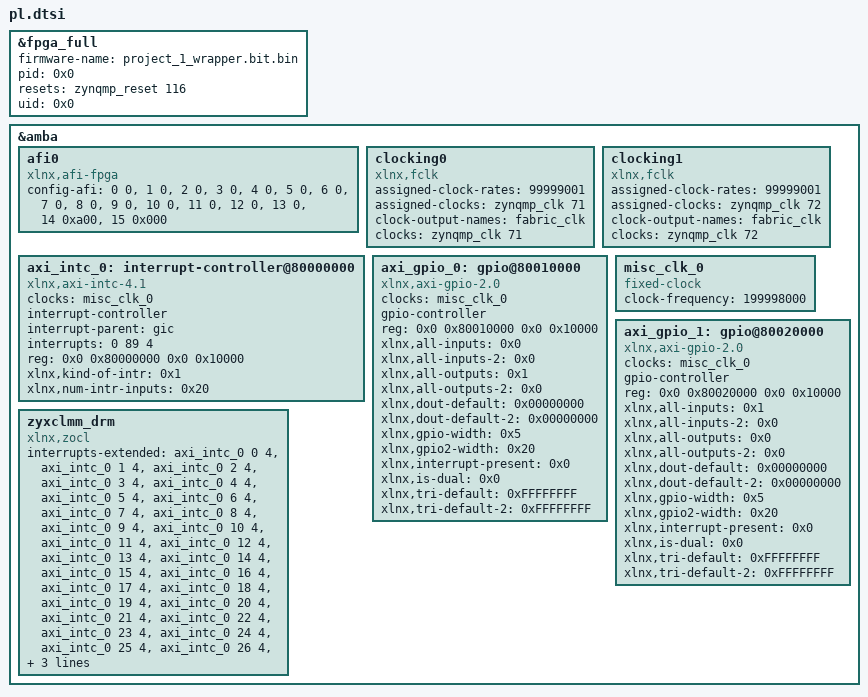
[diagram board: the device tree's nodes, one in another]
/*
 * CAUTION: This file is automatically generated by Xilinx.
 * Version: XSCT 2023.2
 * Today is: Thu Nov 14 10:54:46 2024
 */


/dts-v1/;
/plugin/;
&fpga_full {
	firmware-name = "project_1_wrapper.bit.bin";
	pid = <0x0>;
	resets = <&zynqmp_reset 116>;
	uid = <0x0>;
};
&amba {
	#address-cells = <2>;
	#size-cells = <2>;
	afi0: afi0 {
		compatible = "xlnx,afi-fpga";
		config-afi = < 0 0>, <1 0>, <2 0>, <3 0>, <4 0>, <5 0>, <6 0>, <7 0>, <8 0>, <9 0>, <10 0>, <11 0>, <12 0>, <13 0>, <14 0xa00>, <15 0x000>;
	};
	clocking0: clocking0 {
		#clock-cells = <0>;
		assigned-clock-rates = <99999001>;
		assigned-clocks = <&zynqmp_clk 71>;
		clock-output-names = "fabric_clk";
		clocks = <&zynqmp_clk 71>;
		compatible = "xlnx,fclk";
	};
	clocking1: clocking1 {
		#clock-cells = <0>;
		assigned-clock-rates = <99999001>;
		assigned-clocks = <&zynqmp_clk 72>;
		clock-output-names = "fabric_clk";
		clocks = <&zynqmp_clk 72>;
		compatible = "xlnx,fclk";
	};
	axi_intc_0: interrupt-controller@80000000 {
		#interrupt-cells = <2>;
		clock-names = "s_axi_aclk";
		clocks = <&misc_clk_0>;
		compatible = "xlnx,axi-intc-4.1", "xlnx,xps-intc-1.00.a";
		interrupt-controller ;
		interrupt-names = "irq";
		interrupt-parent = <&gic>;
		interrupts = <0 89 4>;
		reg = <0x0 0x80000000 0x0 0x10000>;
		xlnx,kind-of-intr = <0x1>;
		xlnx,num-intr-inputs = <0x20>;
	};
	axi_gpio_0: gpio@80010000 {
		#gpio-cells = <2>;
		clock-names = "s_axi_aclk";
		clocks = <&misc_clk_0>;
		compatible = "xlnx,axi-gpio-2.0", "xlnx,xps-gpio-1.00.a";
		gpio-controller ;
		reg = <0x0 0x80010000 0x0 0x10000>;
		xlnx,all-inputs = <0x0>;
		xlnx,all-inputs-2 = <0x0>;
		xlnx,all-outputs = <0x1>;
		xlnx,all-outputs-2 = <0x0>;
		xlnx,dout-default = <0x00000000>;
		xlnx,dout-default-2 = <0x00000000>;
		xlnx,gpio-width = <0x5>;
		xlnx,gpio2-width = <0x20>;
		xlnx,interrupt-present = <0x0>;
		xlnx,is-dual = <0x0>;
		xlnx,tri-default = <0xFFFFFFFF>;
		xlnx,tri-default-2 = <0xFFFFFFFF>;
	};
	misc_clk_0: misc_clk_0 {
		#clock-cells = <0>;
		clock-frequency = <199998000>;
		compatible = "fixed-clock";
	};
	axi_gpio_1: gpio@80020000 {
		#gpio-cells = <2>;
		clock-names = "s_axi_aclk";
		clocks = <&misc_clk_0>;
		compatible = "xlnx,axi-gpio-2.0", "xlnx,xps-gpio-1.00.a";
		gpio-controller ;
		reg = <0x0 0x80020000 0x0 0x10000>;
		xlnx,all-inputs = <0x1>;
		xlnx,all-inputs-2 = <0x0>;
		xlnx,all-outputs = <0x0>;
		xlnx,all-outputs-2 = <0x0>;
		xlnx,dout-default = <0x00000000>;
		xlnx,dout-default-2 = <0x00000000>;
		xlnx,gpio-width = <0x5>;
		xlnx,gpio2-width = <0x20>;
		xlnx,interrupt-present = <0x0>;
		xlnx,is-dual = <0x0>;
		xlnx,tri-default = <0xFFFFFFFF>;
		xlnx,tri-default-2 = <0xFFFFFFFF>;
	};
	zyxclmm_drm {
		compatible = "xlnx,zocl";
		interrupts-extended = <&axi_intc_0 0 4>, <&axi_intc_0 1 4>, <&axi_intc_0 2 4>, <&axi_intc_0 3 4>, <&axi_intc_0 4 4>, <&axi_intc_0 5 4>, <&axi_intc_0 6 4>, <&axi_intc_0 7 4>, <&axi_intc_0 8 4>, <&axi_intc_0 9 4>,
<&axi_intc_0 10 4>, <&axi_intc_0 11 4>, <&axi_intc_0 12 4>, <&axi_intc_0 13 4>, <&axi_intc_0 14 4>,
<&axi_intc_0 15 4>, <&axi_intc_0 16 4>, <&axi_intc_0 17 4>, <&axi_intc_0 18 4>, <&axi_intc_0 19 4>,
<&axi_intc_0 20 4>, <&axi_intc_0 21 4>, <&axi_intc_0 22 4>, <&axi_intc_0 23 4>, <&axi_intc_0 24 4>,
<&axi_intc_0 25 4>, <&axi_intc_0 26 4>, <&axi_intc_0 27 4>, <&axi_intc_0 28 4>, <&axi_intc_0 29 4>,
<&axi_intc_0 30 4>, <&axi_intc_0 31 4 >;
	};
};
